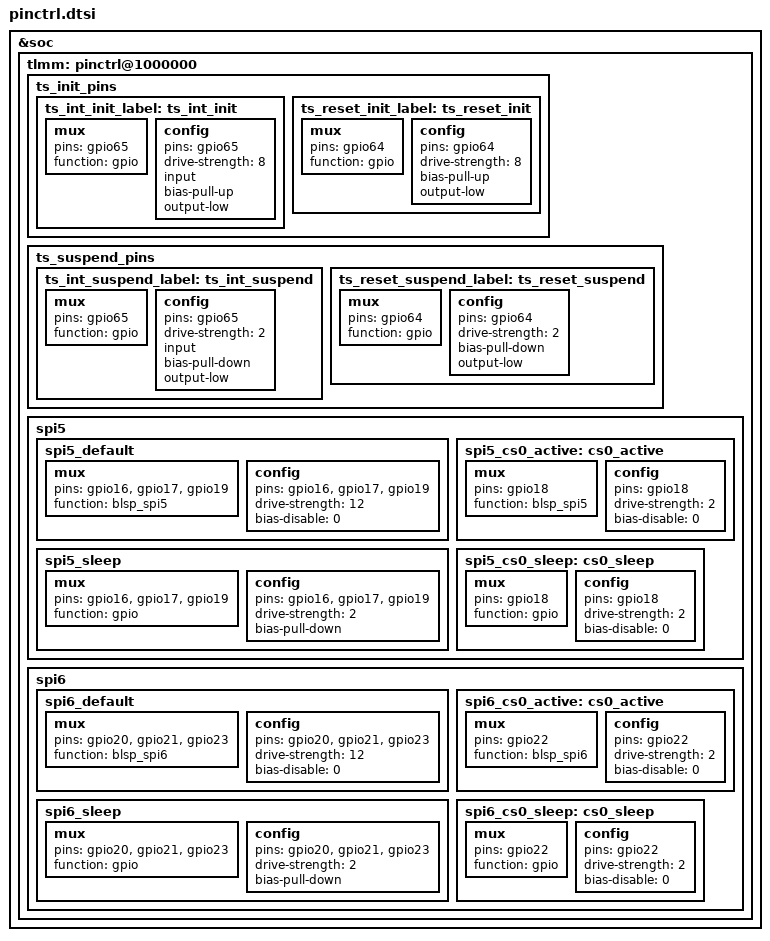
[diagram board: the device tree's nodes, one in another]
&tlmm {
    spi5 {
        spi5_default: spi5_default {
            /* active state */
            mux {
                /* MOSI, MISO, CLK */
                pins = "gpio16", "gpio17", "gpio19";
                function = "blsp_spi5";
            };

            config {
                pins = "gpio16", "gpio17", "gpio19";
                drive-strength = <12>; /* 12 MA */
                bias-disable = <0>; /* No PULL */
            };
        };

        spi5_sleep: spi5_sleep {
            /* suspended state */
            mux {
                /* MOSI, MISO, CLK */
                pins = "gpio16", "gpio17", "gpio19";
                function = "gpio";
            };

            config {
                pins = "gpio16", "gpio17", "gpio19";
                drive-strength = <2>; /* 2 MA */
                bias-pull-down; /* PULL Down */
            };
        };

        spi5_cs0_active: cs0_active {
            /* CS */
            mux {
                pins = "gpio18";
                function = "blsp_spi5";
            };

            config {
                pins = "gpio18";
                drive-strength = <2>;
                bias-disable = <0>;
            };
        };

        spi5_cs0_sleep: cs0_sleep {
            /* CS */
            mux {
                pins = "gpio18";
                function = "gpio";
            };

            config {
                pins = "gpio18";
                drive-strength = <2>;
                bias-disable = <0>;
            };
        };
	};

	spi6 {
		spi6_default: spi6_default {
			/* active state */
			mux {
				/* MOSI, MISO, CLK */
				pins = "gpio20", "gpio21", "gpio23";
				function = "blsp_spi6";
			};

			config {
				pins = "gpio20", "gpio21", "gpio23";
				drive-strength = <12>; /* 12 MA */
				bias-disable = <0>; /* No PULL */
			};
		};

		spi6_sleep: spi6_sleep {
			/* suspended state */
			mux {
				/* MOSI, MISO, CLK */
				pins = "gpio20", "gpio21", "gpio23";
				function = "gpio";
			};

			config {
				pins = "gpio20", "gpio21", "gpio23";
				drive-strength = <2>; /* 2 MA */
				bias-pull-down; /* PULL Down */
			};
		};

		spi6_cs0_active: cs0_active {
			/* CS */
			mux {
				pins = "gpio22";
				function = "blsp_spi6";
			};

			config {
				pins = "gpio22";
				drive-strength = <2>;
				bias-disable = <0>;
			};
		};

		spi6_cs0_sleep: cs0_sleep {
			/* CS */
			mux {
				pins = "gpio22";
				function = "gpio";
			};

			config {
				pins = "gpio22";
				drive-strength = <2>;
				bias-disable = <0>;
			};
		};
	};
};

&soc {
    tlmm: pinctrl@1000000 {
        ts_init_pins: ts_init_pins {
            ts_int_init_label: ts_int_init {
                mux {
                    pins = "gpio65";
                    function = "gpio";
                };
                config {
                    pins = "gpio65";
                    drive-strength = <8>;
                    input;
                    bias-pull-up;
                    output-low;
                };
            };

            ts_reset_init_label: ts_reset_init {
                mux {
                    pins = "gpio64";
                    function = "gpio";
                };
                config {
                    pins = "gpio64";
                    drive-strength = <8>;
                    bias-pull-up;
                    output-low;
                };
            };
        };

        ts_suspend_pins: ts_suspend_pins {
            ts_int_suspend_label: ts_int_suspend {
                mux {
                    pins = "gpio65";
                    function = "gpio";
                };
                config {
                    pins = "gpio65";
                    drive-strength = <2>;
                    input;
                    bias-pull-down;
                    output-low;
                };
            };

            ts_reset_suspend_label: ts_reset_suspend {
                mux {
                    pins = "gpio64";
                    function = "gpio";
                };
                config {
                    pins = "gpio64";
                    drive-strength = <2>;
                    bias-pull-down;
                    output-low;
                };
            };
        };
    };
};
